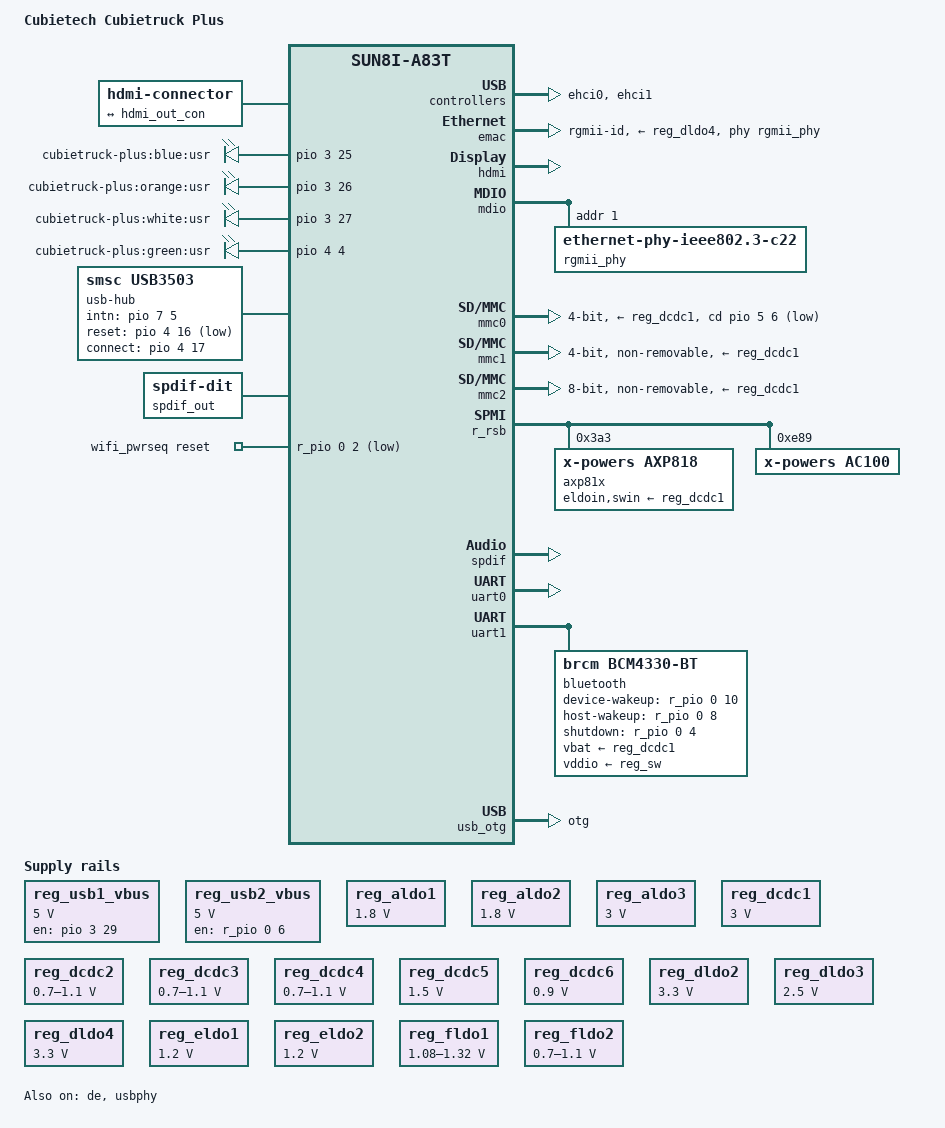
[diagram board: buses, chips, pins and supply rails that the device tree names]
/dts-v1/;
#include "sun8i-a83t.dtsi"
#include <dt-bindings/gpio/gpio.h>
/ {
	model = "Cubietech Cubietruck Plus";
	compatible = "cubietech,cubietruck-plus", "allwinner,sun8i-a83t";
	aliases {
		ethernet0 = &emac;
		serial0 = &uart0;
	};
	chosen {
		stdout-path = "serial0:115200n8";
	};
	hdmi-connector {
		compatible = "hdmi-connector";
		type = "a";
		port {
			hdmi_con_in: endpoint {
				remote-endpoint = <&hdmi_out_con>;
			};
		};
	};
	leds {
		compatible = "gpio-leds";
		led-0 {
			label = "cubietruck-plus:blue:usr";
			gpios = <&pio 3 25 GPIO_ACTIVE_HIGH>;  
		};
		led-1 {
			label = "cubietruck-plus:orange:usr";
			gpios = <&pio 3 26 GPIO_ACTIVE_HIGH>;  
		};
		led-2 {
			label = "cubietruck-plus:white:usr";
			gpios = <&pio 3 27 GPIO_ACTIVE_HIGH>;  
		};
		led-3 {
			label = "cubietruck-plus:green:usr";
			gpios = <&pio 4 4 GPIO_ACTIVE_HIGH>;  
		};
	};
	usb-hub {
		compatible = "smsc,usb3503";
		initial-mode = <1>;  
		disabled-ports = <1>;
		intn-gpios = <&pio 7 5 GPIO_ACTIVE_HIGH>;  
		reset-gpios = <&pio 4 16 GPIO_ACTIVE_LOW>;  
		connect-gpios = <&pio 4 17 GPIO_ACTIVE_HIGH>;  
		refclk-frequency = <19200000>;
	};
	reg_usb1_vbus: reg-usb1-vbus {
		compatible = "regulator-fixed";
		regulator-name = "usb1-vbus";
		regulator-min-microvolt = <5000000>;
		regulator-max-microvolt = <5000000>;
		regulator-boot-on;
		enable-active-high;
		gpio = <&pio 3 29 GPIO_ACTIVE_HIGH>;  
	};
	reg_usb2_vbus: reg-usb2-vbus {
		compatible = "regulator-fixed";
		regulator-name = "usb2-vbus";
		regulator-min-microvolt = <5000000>;
		regulator-max-microvolt = <5000000>;
		regulator-boot-on;
		enable-active-high;
		gpio = <&r_pio 0 6 GPIO_ACTIVE_HIGH>;  
	};
	sound {
		compatible = "simple-audio-card";
		simple-audio-card,name = "On-board SPDIF";
		simple-audio-card,cpu {
			sound-dai = <&spdif>;
		};
		simple-audio-card,codec {
			sound-dai = <&spdif_out>;
		};
	};
	spdif_out: spdif-out {
		#sound-dai-cells = <0>;
		compatible = "linux,spdif-dit";
	};
	wifi_pwrseq: wifi_pwrseq {
		compatible = "mmc-pwrseq-simple";
		clocks = <&ac100_rtc 1>;
		clock-names = "ext_clock";
		assigned-clocks = <&ac100_rtc 1>;
		assigned-clock-rates = <32768>;
		reset-gpios = <&r_pio 0 2 GPIO_ACTIVE_LOW>;  
	};
};
&cpu0 {
	cpu-supply = <&reg_dcdc2>;
};
&cpu100 {
	cpu-supply = <&reg_dcdc3>;
};
&de {
	status = "okay";
};
&ehci0 {
	status = "okay";
};
&ehci1 {
	status = "okay";
};
&emac {
	pinctrl-names = "default";
	pinctrl-0 = <&emac_rgmii_pins>;
	phy-supply = <&reg_dldo4>;
	phy-handle = <&rgmii_phy>;
	phy-mode = "rgmii-id";
	status = "okay";
};
&hdmi {
	status = "okay";
};
&hdmi_out {
	hdmi_out_con: endpoint {
		remote-endpoint = <&hdmi_con_in>;
	};
};
&mdio {
	rgmii_phy: ethernet-phy@1 {
		compatible = "ethernet-phy-ieee802.3-c22";
		reg = <1>;
	};
};
&mmc0 {
	pinctrl-names = "default";
	pinctrl-0 = <&mmc0_pins>;
	vmmc-supply = <&reg_dcdc1>;
	bus-width = <4>;
	cd-gpios = <&pio 5 6 GPIO_ACTIVE_LOW>;  
	status = "okay";
};
&mmc1 {
	vmmc-supply = <&reg_dcdc1>;
	vqmmc-supply = <&reg_sw>;
	mmc-pwrseq = <&wifi_pwrseq>;
	bus-width = <4>;
	non-removable;
	status = "okay";
};
&mmc2 {
	pinctrl-names = "default";
	pinctrl-0 = <&mmc2_8bit_emmc_pins>;
	vmmc-supply = <&reg_dcdc1>;
	bus-width = <8>;
	non-removable;
	cap-mmc-hw-reset;
	status = "okay";
};
&r_rsb {
	status = "okay";
	axp81x: pmic@3a3 {
		compatible = "x-powers,axp818", "x-powers,axp813";
		reg = <0x3a3>;
		interrupt-parent = <&r_intc>;
		interrupts = <GIC_SPI 32 IRQ_TYPE_LEVEL_LOW>;
		eldoin-supply = <&reg_dcdc1>;
		swin-supply = <&reg_dcdc1>;
		x-powers,drive-vbus-en;
	};
	ac100: codec@e89 {
		compatible = "x-powers,ac100";
		reg = <0xe89>;
		ac100_codec: codec {
			compatible = "x-powers,ac100-codec";
			interrupt-parent = <&r_pio>;
			interrupts = <0 11 IRQ_TYPE_LEVEL_LOW>;  
			#clock-cells = <0>;
			clock-output-names = "4M_adda";
		};
		ac100_rtc: rtc {
			compatible = "x-powers,ac100-rtc";
			interrupt-parent = <&r_intc>;
			interrupts = <GIC_SPI 32 IRQ_TYPE_LEVEL_LOW>;
			clocks = <&ac100_codec>;
			#clock-cells = <1>;
			clock-output-names = "cko1_rtc",
					     "cko2_rtc",
					     "cko3_rtc";
		};
	};
};
#include "axp81x.dtsi"
&ac_power_supply {
	status = "okay";
};
&battery_power_supply {
	status = "okay";
};
&reg_aldo1 {
	regulator-always-on;
	regulator-min-microvolt = <1800000>;
	regulator-max-microvolt = <1800000>;
	regulator-name = "vcc-1v8";
};
&reg_aldo2 {
	regulator-always-on;
	regulator-min-microvolt = <1800000>;
	regulator-max-microvolt = <1800000>;
	regulator-name = "dram-pll";
};
&reg_aldo3 {
	regulator-always-on;
	regulator-min-microvolt = <3000000>;
	regulator-max-microvolt = <3000000>;
	regulator-name = "avcc";
};
&reg_dcdc1 {
	regulator-always-on;
	regulator-min-microvolt = <3000000>;
	regulator-max-microvolt = <3000000>;
	regulator-name = "vcc-3v";
};
&reg_dcdc2 {
	regulator-always-on;
	regulator-min-microvolt = <700000>;
	regulator-max-microvolt = <1100000>;
	regulator-name = "vdd-cpua";
};
&reg_dcdc3 {
	regulator-always-on;
	regulator-min-microvolt = <700000>;
	regulator-max-microvolt = <1100000>;
	regulator-name = "vdd-cpub";
};
&reg_dcdc4 {
	regulator-min-microvolt = <700000>;
	regulator-max-microvolt = <1100000>;
	regulator-name = "vdd-gpu";
};
&reg_dcdc5 {
	regulator-always-on;
	regulator-min-microvolt = <1500000>;
	regulator-max-microvolt = <1500000>;
	regulator-name = "vcc-dram";
};
&reg_dcdc6 {
	regulator-always-on;
	regulator-min-microvolt = <900000>;
	regulator-max-microvolt = <900000>;
	regulator-name = "vdd-sys";
};
&reg_dldo2 {
	regulator-min-microvolt = <3300000>;
	regulator-max-microvolt = <3300000>;
	regulator-name = "dp-pwr";
};
&reg_dldo3 {
	regulator-always-on;
	regulator-min-microvolt = <2500000>;
	regulator-max-microvolt = <2500000>;
	regulator-name = "ephy-io";
};
&reg_dldo4 {
	regulator-enable-ramp-delay = <100000>;
	regulator-min-microvolt = <3300000>;
	regulator-max-microvolt = <3300000>;
	regulator-name = "ephy";
};
&reg_drivevbus {
	regulator-name = "usb0-vbus";
	status = "okay";
};
&reg_eldo1 {
	regulator-min-microvolt = <1200000>;
	regulator-max-microvolt = <1200000>;
	regulator-name = "dp-bridge-1";
};
&reg_eldo2 {
	regulator-min-microvolt = <1200000>;
	regulator-max-microvolt = <1200000>;
	regulator-name = "dp-bridge-2";
};
&reg_fldo1 {
	regulator-always-on;
	regulator-min-microvolt = <1080000>;
	regulator-max-microvolt = <1320000>;
	regulator-name = "vdd12-hsic";
};
&reg_fldo2 {
	regulator-always-on;
	regulator-min-microvolt = <700000>;
	regulator-max-microvolt = <1100000>;
	regulator-name = "vdd-cpus";
};
&reg_rtc_ldo {
	regulator-name = "vcc-rtc";
};
&reg_sw {
	regulator-name = "vcc-wifi-io";
};
&spdif {
	status = "okay";
};
&uart0 {
	pinctrl-names = "default";
	pinctrl-0 = <&uart0_pb_pins>;
	status = "okay";
};
&uart1 {
	pinctrl-names = "default";
	pinctrl-0 = <&uart1_pins>, <&uart1_rts_cts_pins>;
	uart-has-rtscts;
	status = "okay";
	bluetooth {
		compatible = "brcm,bcm4330-bt";
		clocks = <&ac100_rtc 1>;
		clock-names = "lpo";
		vbat-supply = <&reg_dcdc1>;
		vddio-supply = <&reg_sw>;
		device-wakeup-gpios = <&r_pio 0 10 GPIO_ACTIVE_HIGH>;  
		host-wakeup-gpios = <&r_pio 0 8 GPIO_ACTIVE_HIGH>;  
		shutdown-gpios = <&r_pio 0 4 GPIO_ACTIVE_HIGH>;  
	};
};
&usb_otg {
	dr_mode = "otg";
	status = "okay";
};
&usb_power_supply {
	status = "okay";
};
&usbphy {
	usb0_id_det-gpios = <&pio 7 11 GPIO_ACTIVE_HIGH>;  
	usb0_vbus_power-supply = <&usb_power_supply>;
	usb0_vbus-supply = <&reg_drivevbus>;
	usb1_vbus-supply = <&reg_usb1_vbus>;
	usb2_vbus-supply = <&reg_usb2_vbus>;
	status = "okay";
};
